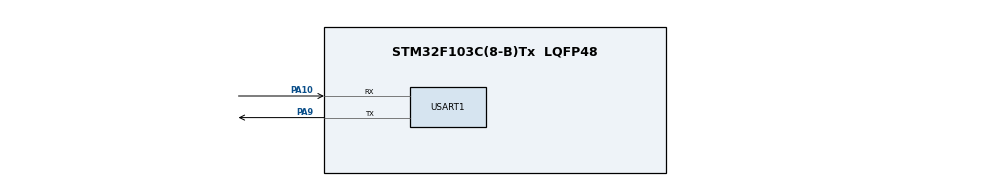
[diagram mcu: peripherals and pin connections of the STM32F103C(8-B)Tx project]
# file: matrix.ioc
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Mcu.Family=STM32F1
Mcu.Name=STM32F103C(8-B)Tx
Mcu.Package=LQFP48
NVIC.PriorityGroup=NVIC_PRIORITYGROUP_4
PA10.Mode=Asynchronous
PA10.Signal=USART1_RX
PA13.Mode=Serial_Wire
PA13.Signal=SYS_JTMS-SWDIO
PA14.Mode=Serial_Wire
PA14.Signal=SYS_JTCK-SWCLK
PA9.Mode=Asynchronous
PA9.Signal=USART1_TX
ProjectManager.HeapSize=0x200
ProjectManager.StackSize=0x400
ProjectManager.TargetToolchain=STM32CubeIDE
RCC.APB1Freq_Value=8000000
RCC.APB2Freq_Value=8000000
USART1.VirtualMode=VM_ASYNC
board=custom

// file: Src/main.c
/* USER CODE BEGIN Header */
/**
  ******************************************************************************
  * @file           : main.c
  * @brief          : Main program body
  ******************************************************************************
  * @attention
  *
  * <h2><center>&copy; Copyright (c) 2019 STMicroelectronics.
  * All rights reserved.</center></h2>
  *
  * This software component is licensed by ST under BSD 3-Clause license,
  * the "License"; You may not use this file except in compliance with the
  * License. You may obtain a copy of the License at:
  *                        opensource.org/licenses/BSD-3-Clause
  *
  ******************************************************************************
  */
/* USER CODE END Header */

#include "main.h"

UART_HandleTypeDef huart1;

void SystemClock_Config(void);
static void MX_GPIO_Init(void);
static void MX_USART1_UART_Init(void);

int main(void)
{

  /* MCU Configuration--------------------------------------------------------*/

  /* Reset of all peripherals, Initializes the Flash interface and the Systick. */
  HAL_Init();

  /* Configure the system clock */
  SystemClock_Config();

  /* Initialize all configured peripherals */
  MX_GPIO_Init();
  MX_USART1_UART_Init();
  /* USER CODE BEGIN 2 */
  Mat m,m3,m4,m5;
  double u_k_1; const double y_meas[9]; const double x_hat_plus_k_1[7];
                             const double P_plus_k_1[49]; const double Q_k[49]; const double
                             R_k[81]; double T; double tau_rx; double tau_ry; double tau_rz;
                             double ax_inertial; double ay_inertial; double az_inertial; double
                             mx_inertial; double my_inertial; double mz_inertial; double
                             x_hat_plus_k[7]; double P_plus_k[49];
  /* USER CODE END 2 */

  /* Infinite loop */
  while (1)
  {

    /* USER CODE BEGIN 3 */
	  m = init_mat(4,4);
	  	      m.data[0 * 4 + 0] = 4.4;
	  	      m.data[0 * 4 + 1] = 3;
	  	      m.data[0 * 4 + 2] = 1;
	  	      m.data[0 * 4 + 3] = 1;

	  	      m.data[1 * 4 + 0] = 1;
	  	      m.data[1 * 4 + 1] = 2;
	  	      m.data[1 * 4 + 2] = 1;
	  	      m.data[1 * 4 + 3] = 1;

	  	      m.data[2 * 4 + 0] = 1;
	  	      m.data[2 * 4 + 1] = 0.5;
	  	      m.data[2 * 4 + 2] = 9.3461;
	  	      m.data[2 * 4 + 3] = 1;

	  	      m.data[3 * 4 + 0] = 1;
	  	      m.data[3 * 4 + 1] = 0.5;
	  	      m.data[3 * 4 + 2] = 4;
	  	      m.data[3 * 4 + 3] = 3;
	  	      m3 = inverse(m);
              free_mat(m);
              free_mat(m3);
              IMU_EKF( u_k_1,  y_meas[9], x_hat_plus_k_1[7],P_plus_k_1[49],  Q_k[49],
                           R_k[81],  T,  tau_rx,  tau_ry,  tau_rz,
                            ax_inertial,  ay_inertial,  az_inertial,
                           mx_inertial,  my_inertial,  mz_inertial,
                           x_hat_plus_k[7],  P_plus_k[49]);
//	  	      m3 = cholesky(m);
//	  	      m4 = adjoint(m);
//	  	      // Mat m4 =  cholsky_inv(m3);
//	  	       // cout<< det_cholesky(m3)*det_cholesky(m3) << "\n";
//
//	  	      m5 = inverse(m);
  }
  /* USER CODE END 3 */
}

void SystemClock_Config(void)
{
  RCC_OscInitTypeDef RCC_OscInitStruct = {0};
  RCC_ClkInitTypeDef RCC_ClkInitStruct = {0};

  /** Initializes the CPU, AHB and APB busses clocks
  */
  RCC_OscInitStruct.OscillatorType = RCC_OSCILLATORTYPE_HSI;
  RCC_OscInitStruct.HSIState = RCC_HSI_ON;
  RCC_OscInitStruct.HSICalibrationValue = RCC_HSICALIBRATION_DEFAULT;
  RCC_OscInitStruct.PLL.PLLState = RCC_PLL_NONE;
  if (HAL_RCC_OscConfig(&RCC_OscInitStruct) != HAL_OK)
  {
    Error_Handler();
  }
  /** Initializes the CPU, AHB and APB busses clocks
  */
  RCC_ClkInitStruct.ClockType = RCC_CLOCKTYPE_HCLK|RCC_CLOCKTYPE_SYSCLK
                              |RCC_CLOCKTYPE_PCLK1|RCC_CLOCKTYPE_PCLK2;
  RCC_ClkInitStruct.SYSCLKSource = RCC_SYSCLKSOURCE_HSI;
  RCC_ClkInitStruct.AHBCLKDivider = RCC_SYSCLK_DIV1;
  RCC_ClkInitStruct.APB1CLKDivider = RCC_HCLK_DIV1;
  RCC_ClkInitStruct.APB2CLKDivider = RCC_HCLK_DIV1;

  if (HAL_RCC_ClockConfig(&RCC_ClkInitStruct, FLASH_LATENCY_0) != HAL_OK)
  {
    Error_Handler();
  }
}

static void MX_USART1_UART_Init(void)
{

  huart1.Instance = USART1;
  huart1.Init.BaudRate = 115200;
  huart1.Init.WordLength = UART_WORDLENGTH_8B;
  huart1.Init.StopBits = UART_STOPBITS_1;
  huart1.Init.Parity = UART_PARITY_NONE;
  huart1.Init.Mode = UART_MODE_TX_RX;
  huart1.Init.HwFlowCtl = UART_HWCONTROL_NONE;
  huart1.Init.OverSampling = UART_OVERSAMPLING_16;
  if (HAL_UART_Init(&huart1) != HAL_OK)
  {
    Error_Handler();
  }

}

static void MX_GPIO_Init(void)
{

  /* GPIO Ports Clock Enable */
  __HAL_RCC_GPIOA_CLK_ENABLE();

}

void Error_Handler(void)
{
}

/************************ (C) COPYRIGHT STMicroelectronics *****END OF FILE****/
